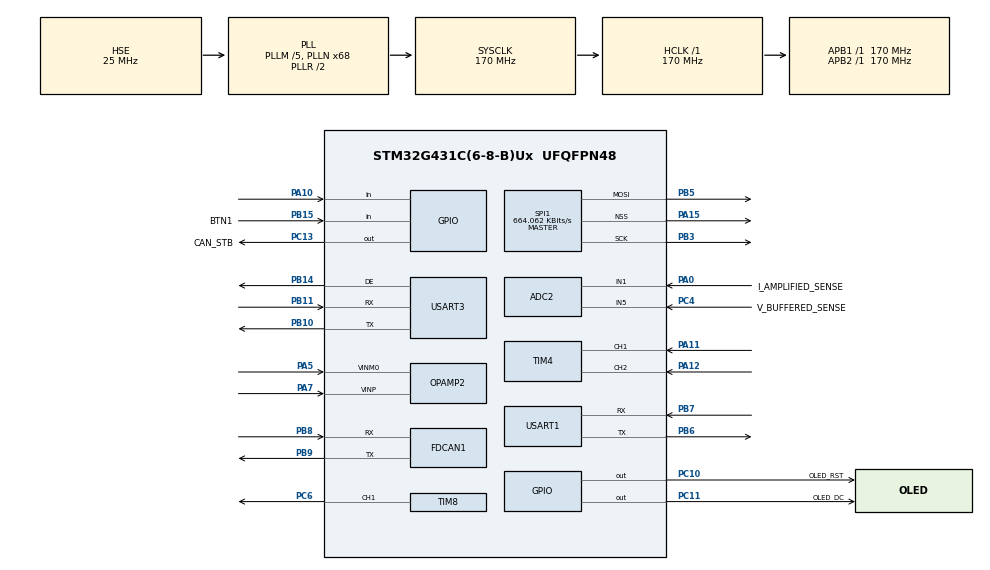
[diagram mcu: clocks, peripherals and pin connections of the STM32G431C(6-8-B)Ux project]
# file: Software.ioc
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ADC2.Channel-0\#ChannelRegularConversion=ADC_CHANNEL_5
ADC2.Channel-1\#ChannelRegularConversion=ADC_CHANNEL_1
ADC2.Channel-2\#ChannelRegularConversion=ADC_CHANNEL_VOPAMP2
ADC2.ClockPrescaler=ADC_CLOCK_ASYNC_DIV4
ADC2.ContinuousConvMode=ENABLE
ADC2.DMAContinuousRequests=ENABLE
ADC2.ExternalTrigConv=ADC_EXTERNALTRIG_T3_TRGO
ADC2.NbrOfConversion=3
ADC2.NbrOfConversionFlag=1
ADC2.OffsetNumber-0\#ChannelRegularConversion=ADC_OFFSET_NONE
ADC2.OffsetNumber-1\#ChannelRegularConversion=ADC_OFFSET_NONE
ADC2.OffsetNumber-2\#ChannelRegularConversion=ADC_OFFSET_NONE
ADC2.Overrun=ADC_OVR_DATA_OVERWRITTEN
ADC2.Rank-0\#ChannelRegularConversion=1
ADC2.Rank-1\#ChannelRegularConversion=2
ADC2.Rank-2\#ChannelRegularConversion=3
ADC2.SamplingTime-0\#ChannelRegularConversion=ADC_SAMPLETIME_92CYCLES_5
ADC2.SamplingTime-1\#ChannelRegularConversion=ADC_SAMPLETIME_92CYCLES_5
ADC2.SamplingTime-2\#ChannelRegularConversion=ADC_SAMPLETIME_92CYCLES_5
Dma.ADC2.0.Direction=DMA_PERIPH_TO_MEMORY
Dma.ADC2.0.EventEnable=DISABLE
Dma.ADC2.0.Instance=DMA2_Channel1
Dma.ADC2.0.MemDataAlignment=DMA_MDATAALIGN_HALFWORD
Dma.ADC2.0.MemInc=DMA_MINC_ENABLE
Dma.ADC2.0.Mode=DMA_CIRCULAR
Dma.ADC2.0.PeriphDataAlignment=DMA_PDATAALIGN_HALFWORD
Dma.ADC2.0.PeriphInc=DMA_PINC_DISABLE
Dma.ADC2.0.Polarity=HAL_DMAMUX_REQ_GEN_RISING
Dma.ADC2.0.Priority=DMA_PRIORITY_HIGH
Dma.ADC2.0.RequestNumber=1
Dma.ADC2.0.SignalID=NONE
Dma.ADC2.0.SyncEnable=DISABLE
Dma.ADC2.0.SyncPolarity=HAL_DMAMUX_SYNC_NO_EVENT
Dma.ADC2.0.SyncRequestNumber=1
Dma.ADC2.0.SyncSignalID=NONE
Dma.Request0=ADC2
FDCAN1.CalculateBaudRateNominal=2125000
FDCAN1.CalculateTimeBitNominal=470
FDCAN1.CalculateTimeQuantumNominal=94.11764705882354
Mcu.Family=STM32G4
Mcu.Name=STM32G431C(6-8-B)Ux
Mcu.Package=UFQFPN48
NVIC.DMA2_Channel1_IRQn=true\:0\:0\:false\:false\:true\:false\:true\:true
NVIC.PriorityGroup=NVIC_PRIORITYGROUP_4
OPAMP2.PgaGain=OPAMP_PGA_GAIN_64_OR_MINUS_63
OPAMP2.PowerMode=OPAMP_POWERMODE_HIGHSPEED
PA0.GPIO_Label=I_AMPLIFIED_SENSE
PA0.Mode=IN1-Single-Ended
PA0.Signal=ADC2_IN1
PA10.Signal=GPIO_Input
PA11.Signal=S_TIM4_CH1
PA12.Signal=S_TIM4_CH2
PA13.Mode=Serial_Wire
PA13.Signal=SYS_JTMS-SWDIO
PA14.Mode=Serial_Wire
PA14.Signal=SYS_JTCK-SWCLK
PA15.Mode=NSS_Signal_Hard_Output
PA15.Signal=SPI1_NSS
PA5.Mode=PGA Internally connected_IO0_BIAS
PA5.Signal=OPAMP2_VINM0
PA7.Mode=PGA Internally connected_IO0_BIAS
PA7.Signal=OPAMP2_VINP
PB10.Mode=Asynchronous
PB10.Signal=USART3_TX
PB11.Mode=Asynchronous
PB11.Signal=USART3_RX
PB14.Mode=Hardware Flow Control (RS485)
PB14.Signal=USART3_DE
PB15.GPIO_Label=BTN1
PB15.Signal=GPIO_Input
PB3.Mode=TX_Only_Simplex_Unidirect_Master
PB3.Signal=SPI1_SCK
PB5.Mode=TX_Only_Simplex_Unidirect_Master
PB5.Signal=SPI1_MOSI
PB6.Mode=Asynchronous
PB6.Signal=USART1_TX
PB7.Mode=Asynchronous
PB7.Signal=USART1_RX
PB8-BOOT0.Mode=FDCAN_Activate
PB8-BOOT0.Signal=FDCAN1_RX
PB9.Mode=FDCAN_Activate
PB9.Signal=FDCAN1_TX
PC10.GPIO_Label=OLED_RST
PC10.Signal=GPIO_Output
PC11.GPIO_Label=OLED_DC
PC11.Signal=GPIO_Output
PC13.GPIO_Label=CAN_STB
PC13.Signal=GPIO_Output
PC4.GPIO_Label=V_BUFFERED_SENSE
PC4.Mode=IN5-Single-Ended
PC4.Signal=ADC2_IN5
PC6.Signal=S_TIM8_CH1
PF0-OSC_IN.Mode=HSE-External-Oscillator
PF0-OSC_IN.Signal=RCC_OSC_IN
PF1-OSC_OUT.Mode=HSE-External-Oscillator
PF1-OSC_OUT.Signal=RCC_OSC_OUT
ProjectManager.HeapSize=0x200
ProjectManager.StackSize=0x400
ProjectManager.TargetToolchain=Makefile
RCC.ADC12Freq_Value=170000000
RCC.AHBFreq_Value=170000000
RCC.APB1Freq_Value=170000000
RCC.APB1TimFreq_Value=170000000
RCC.APB2Freq_Value=170000000
RCC.APB2TimFreq_Value=170000000
RCC.CortexFreq_Value=170000000
RCC.EXTERNAL_CLOCK_VALUE=12288000
RCC.HCLKFreq_Value=170000000
RCC.HSE_VALUE=25000000
RCC.HSI48_VALUE=48000000
RCC.HSI_VALUE=16000000
RCC.LSE_VALUE=32768
RCC.PLLM=RCC_PLLM_DIV5
RCC.PLLN=68
RCC.PLLSourceVirtual=RCC_PLLSOURCE_HSE
RCC.SYSCLKFreq_VALUE=170000000
RCC.SYSCLKSource=RCC_SYSCLKSOURCE_PLLCLK
RCC.USBFreq_Value=170000000
RCC.VCOOutputFreq_Value=340000000
SH.S_TIM4_CH1.0=TIM4_CH1,Encoder_Interface
SH.S_TIM4_CH2.0=TIM4_CH2,Encoder_Interface
SH.S_TIM8_CH1.0=TIM8_CH1,PWM Generation1 CH1
SPI1.BaudRatePrescaler=SPI_BAUDRATEPRESCALER_256
SPI1.CalculateBaudRate=664.062 KBits/s
SPI1.Direction=SPI_DIRECTION_2LINES
SPI1.Mode=SPI_MODE_MASTER
SPI1.NSSPMode=SPI_NSS_PULSE_DISABLE
SPI1.VirtualNSS=VM_NSSHARD
SPI1.VirtualType=VM_MASTER
TIM1.Channel-PWM\ Generation6\ No\ Output=TIM_CHANNEL_6
TIM3.Channel-Output\ Compare4\ No\ Output=TIM_CHANNEL_4
TIM3.PeriodNoDither=1000-1
TIM3.Prescaler=170-1
TIM3.TIM_MasterOutputTrigger=TIM_TRGO_UPDATE
TIM8.Channel-PWM\ Generation1\ CH1=TIM_CHANNEL_1
TIM8.PeriodNoDither=1000
TIM8.Prescaler=17
USART1.VirtualMode-Asynchronous=VM_ASYNC
USART3.VirtualMode-Asynchronous=VM_ASYNC
USART3.VirtualMode-Hardware\ Flow\ Control\ (RS485)=VM_ASYNC
VP_ADC2_OPAMP_INTERNAL2.Mode=IN-OPAMP2
VP_SYS_VS_DBSignals.Mode=DisableDeadBatterySignals
VP_SYS_V_VREFBUF.Mode=ExternalMode
VP_TIM1_VS_no_output6.Mode=PWM Generation6 No Output
VP_TIM3_VS_ClockSourceINT.Mode=Internal
VP_TIM3_VS_no_output4.Mode=Output Compare4 No Output
board=custom

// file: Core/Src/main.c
/* USER CODE BEGIN Header */
/**
  ******************************************************************************
  * @file           : main.c
  * @brief          : Main program body
  ******************************************************************************
  * @attention
  *
  * Copyright (c) 2023 STMicroelectronics.
  * All rights reserved.
  *
  * This software is licensed under terms that can be found in the LICENSE file
  * in the root directory of this software component.
  * If no LICENSE file comes with this software, it is provided AS-IS.
  *
  ******************************************************************************
  */
/* USER CODE END Header */
#include "main.h"
#include "adc.h"
#include "dma.h"
#include "fdcan.h"
#include "opamp.h"
#include "spi.h"
#include "tim.h"
#include "usart.h"
#include "gpio.h"

void SystemClock_Config(void);

int main(void)
{

  /* MCU Configuration--------------------------------------------------------*/

  /* Reset of all peripherals, Initializes the Flash interface and the Systick. */
  HAL_Init();

  /* Configure the system clock */
  SystemClock_Config();

  /* Initialize all configured peripherals */
  MX_GPIO_Init();
  MX_DMA_Init();
  MX_FDCAN1_Init();
  MX_OPAMP2_Init();
  MX_SPI1_Init();
  MX_ADC2_Init();
  MX_TIM1_Init();
  MX_TIM4_Init();
  MX_USART1_UART_Init();
  MX_USART3_UART_Init();
  MX_TIM8_Init();
  MX_TIM3_Init();
  /* USER CODE BEGIN 2 */

    //HAL_Delay(1000);

    extern void SystemStart();
    SystemStart();
  /* USER CODE END 2 */

  /* Infinite loop */
    while (1) {

    }
}

void SystemClock_Config(void)
{
  RCC_OscInitTypeDef RCC_OscInitStruct = {0};
  RCC_ClkInitTypeDef RCC_ClkInitStruct = {0};

  /** Configure the main internal regulator output voltage
  */
  HAL_PWREx_ControlVoltageScaling(PWR_REGULATOR_VOLTAGE_SCALE1_BOOST);

  /** Initializes the RCC Oscillators according to the specified parameters
  * in the RCC_OscInitTypeDef structure.
  */
  RCC_OscInitStruct.OscillatorType = RCC_OSCILLATORTYPE_HSE;
  RCC_OscInitStruct.HSEState = RCC_HSE_ON;
  RCC_OscInitStruct.PLL.PLLState = RCC_PLL_ON;
  RCC_OscInitStruct.PLL.PLLSource = RCC_PLLSOURCE_HSE;
  RCC_OscInitStruct.PLL.PLLM = RCC_PLLM_DIV5;
  RCC_OscInitStruct.PLL.PLLN = 68;
  RCC_OscInitStruct.PLL.PLLP = RCC_PLLP_DIV2;
  RCC_OscInitStruct.PLL.PLLQ = RCC_PLLQ_DIV2;
  RCC_OscInitStruct.PLL.PLLR = RCC_PLLR_DIV2;
  if (HAL_RCC_OscConfig(&RCC_OscInitStruct) != HAL_OK)
  {
    Error_Handler();
  }

  /** Initializes the CPU, AHB and APB buses clocks
  */
  RCC_ClkInitStruct.ClockType = RCC_CLOCKTYPE_HCLK|RCC_CLOCKTYPE_SYSCLK
                              |RCC_CLOCKTYPE_PCLK1|RCC_CLOCKTYPE_PCLK2;
  RCC_ClkInitStruct.SYSCLKSource = RCC_SYSCLKSOURCE_PLLCLK;
  RCC_ClkInitStruct.AHBCLKDivider = RCC_SYSCLK_DIV1;
  RCC_ClkInitStruct.APB1CLKDivider = RCC_HCLK_DIV1;
  RCC_ClkInitStruct.APB2CLKDivider = RCC_HCLK_DIV1;

  if (HAL_RCC_ClockConfig(&RCC_ClkInitStruct, FLASH_LATENCY_4) != HAL_OK)
  {
    Error_Handler();
  }
}

void Error_Handler(void)
{
    __disable_irq();
    while (1) {
    }
}
